AUTOSAR XML (schema 314)
package /ComponentType
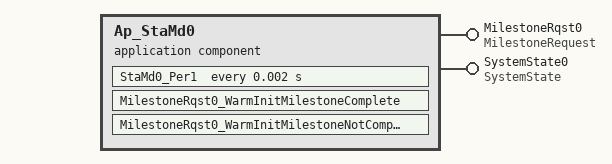
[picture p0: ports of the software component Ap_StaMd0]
  application software component type Ap_StaMd0
    provide port MilestoneRqst0: provided-interface=MilestoneRequest
      provided-com-specs:
        operation=WarmInitMilestoneComplete, queue-length=1
        operation=WarmInitMilestoneNotComplete, queue-length=1
    provide port SystemState0: mode-switch-com-spec{mode-group=Mode, queue-length=1}, provided-interface=SystemState
  internal behavior Ap_StaMd0_InternalBehavior: component=Ap_StaMd0
    operation invoked event OIT_MilestoneRqst0_WarmInitMilestoneComplete_MilestoneRqst0_WarmInitMilestoneComplete: start-on-event=MilestoneRqst0_WarmInitMilestoneComplete, operation=MilestoneRqst0.WarmInitMilestoneComplete
    operation invoked event OIT_MilestoneRqst0_WarmInitMilestoneNotComplete_MilestoneRqst0_WarmInitMilestoneNotComplete: start-on-event=MilestoneRqst0_WarmInitMilestoneNotComplete, operation=MilestoneRqst0.WarmInitMilestoneNotComplete
    timing event TMT_StaMd0_Per1: start-on-event=StaMd0_Per1, period=0.002
    exclusive area StaMds0_MilestoneRqst_WARMINIT_ExclArea
    port-api-options:
      enable-take-address=false, indirect-api=false, port=MilestoneRqst0
      enable-take-address=false, indirect-api=false, port=SystemState0
    runnable MilestoneRqst0_WarmInitMilestoneComplete: can-be-invoked-concurrently=true, can-enter-exclusive-area=StaMds0_MilestoneRqst_WARMINIT_ExclArea
    runnable MilestoneRqst0_WarmInitMilestoneNotComplete: can-be-invoked-concurrently=true, can-enter-exclusive-area=StaMds0_MilestoneRqst_WARMINIT_ExclArea
    runnable StaMd0_Per1
      mode switch point SWITCH_SystemState0_Mode: mode-group=SystemState0.Mode
  swc implementation Ap_StaMd0_Implementation: behavior=Ap_StaMd0_InternalBehavior
    code-descriptors:
      code Code: type=SRC
